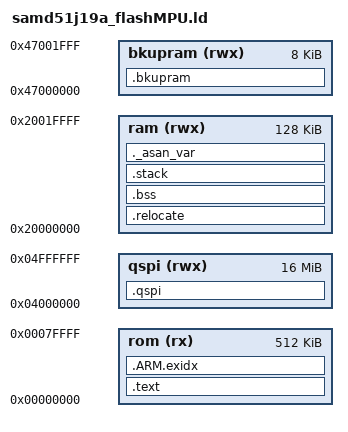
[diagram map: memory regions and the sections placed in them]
/**
 * \file
 *
 * \brief Linker script for running in internal FLASH on the SAMD51J19A
 *
 * Copyright (c) 2019 Microchip Technology Inc.
 *
 * \asf_license_start
 *
 * \page License
 *
 * SPDX-License-Identifier: Apache-2.0
 *
 * Licensed under the Apache License, Version 2.0 (the "License"); you may
 * not use this file except in compliance with the License.
 * You may obtain a copy of the Licence at
 * 
 * http://www.apache.org/licenses/LICENSE-2.0
 * 
 * Unless required by applicable law or agreed to in writing, software
 * distributed under the License is distributed on an AS IS BASIS, WITHOUT
 * WARRANTIES OR CONDITIONS OF ANY KIND, either express or implied.
 * See the License for the specific language governing permissions and
 * limitations under the License.
 *
 * \asf_license_stop
 *
 */


OUTPUT_FORMAT("elf32-littlearm", "elf32-littlearm", "elf32-littlearm")
OUTPUT_ARCH(arm)
SEARCH_DIR(.)

/* Memory Spaces Definitions */
MEMORY
{
  rom      (rx)  : ORIGIN = 0x00000000, LENGTH = 0x00080000
  ram      (rwx) : ORIGIN = 0x20000000, LENGTH = 0x00020000
  bkupram  (rwx) : ORIGIN = 0x47000000, LENGTH = 0x00002000
  qspi     (rwx) : ORIGIN = 0x04000000, LENGTH = 0x01000000
}


/* Initial 32K Flash is used to store kernel functions and
 * initial 512 bytes of RAM is used to store kernel data. */
__privileged_functions_region_size__  = 32K;
__privileged_data_region_size__       = 32K;

__FLASH_segment_start__               = ORIGIN( rom );
__FLASH_segment_end__                 = __FLASH_segment_start__ + LENGTH( rom );

__SRAM_segment_start__                = ORIGIN( ram );
__SRAM_segment_end__                  = __SRAM_segment_start__ + LENGTH( ram );

__privileged_functions_start__        = __FLASH_segment_start__;
__privileged_functions_end__          = __FLASH_segment_start__ + __privileged_functions_region_size__;

__privileged_data_start__             = __SRAM_segment_start__;
__privileged_data_end__               = __SRAM_segment_start__ + __privileged_data_region_size__;



/* The stack size used by the application. NOTE: you need to adjust according to your application. */
/*STACK_SIZE = DEFINED(STACK_SIZE) ? STACK_SIZE : DEFINED(__stack_size__) ? __stack_size__ : 4k;*/


/* Highest address of the user mode stack */
_estack = ORIGIN(ram) + LENGTH(ram); /* end of "RAM_D1" Ram type memory */

_Min_Heap_Size = 4096 ; /* required amount of heap  */
_Min_Stack_Size = 1024 ; /* required amount of stack */



/* Section Definitions */
SECTIONS
{
    


    .text :
    {
        . = ALIGN(4);
        _sfixed = .;
        KEEP(*(.vectors .vectors.*))
         . = ALIGN(4);
        *(privileged_functions)
        . = ALIGN(4);
        FILL(0xDEAD);
        /* Ensure that un-privileged code is placed after the region reserved
         * for privileged kernel code. */
        /* Note that dot (.) actually refers to the byte offset from the start
         * of the current section (.privileged_functions in this case). As a
         * result, setting dot (.) to a value sets the size of the section. */
        . = __privileged_functions_region_size__;
        . = ALIGN(4);
        __syscalls_flash_start__ = .;
        *(freertos_system_calls)
        __syscalls_flash_end__ = .;
        . = ALIGN(4);
        *(.text .text.* .gnu.linkonce.t.*)
        *(.glue_7t) *(.glue_7)
        *(.rodata .rodata* .gnu.linkonce.r.*)
        *(.ARM.extab* .gnu.linkonce.armextab.*)

        /* Support C constructors, and C destructors in both user code
           and the C library. This also provides support for C++ code. */
        . = ALIGN(4);
        KEEP(*(.init))
        . = ALIGN(4);
        __preinit_array_start = .;
        KEEP (*(.preinit_array))
        __preinit_array_end = .;

        . = ALIGN(4);
        __init_array_start = .;
        KEEP (*(SORT(.init_array.*)))
        KEEP (*(.init_array))
        __init_array_end = .;

        . = ALIGN(4);
        KEEP (*crtbegin.o(.ctors))
        KEEP (*(EXCLUDE_FILE (*crtend.o) .ctors))
        KEEP (*(SORT(.ctors.*)))
        KEEP (*crtend.o(.ctors))

        . = ALIGN(4);
        KEEP(*(.fini))

        . = ALIGN(4);
        __fini_array_start = .;
        KEEP (*(.fini_array))
        KEEP (*(SORT(.fini_array.*)))
        __fini_array_end = .;

        KEEP (*crtbegin.o(.dtors))
        KEEP (*(EXCLUDE_FILE (*crtend.o) .dtors))
        KEEP (*(SORT(.dtors.*)))
        KEEP (*crtend.o(.dtors))

        . = ALIGN(4);
        _efixed = .;            /* End of text section */
    } > rom

    /* .ARM.exidx is sorted, so has to go in its own output section.  */
    PROVIDE_HIDDEN (__exidx_start = .);
    .ARM.exidx :
    {
      *(.ARM.exidx* .gnu.linkonce.armexidx.*)
    } > rom
    PROVIDE_HIDDEN (__exidx_end = .);

    . = ALIGN(4);
    _etext = .;

    .relocate : AT (_etext)
    {
        . = ALIGN(4);
        _srelocate = .;
        *(privileged_data)
        . = ALIGN(4);
        FILL(0xDEAD);
        /* Ensure that un-privileged data is placed after the region reserved
         * for privileged kernel data. */
        /* Note that dot (.) actually refers to the byte offset from the start
         * of the current section (.privileged_data in this case). As a result,
         * setting dot (.) to a value sets the size of the section. */
        . = __privileged_data_region_size__;
        *(.ramfunc .ramfunc.*);
        *(.data .data.*);
        . = ALIGN(4);
        _erelocate = .;
    } > ram





    .bkupram (NOLOAD):
    {
        . = ALIGN(8);
        _sbkupram = .;
        *(.bkupram .bkupram.*);
        . = ALIGN(8);
        _ebkupram = .;
    } > bkupram

    .qspi (NOLOAD):
    {
        . = ALIGN(8);
        _sqspi = .;
        *(.qspi .qspi.*);
        . = ALIGN(8);
        _eqspi = .;
    } > qspi

    /* .bss section which is used for uninitialized data */
    .bss (NOLOAD) :
    {
        . = ALIGN(4);
        _sbss = . ;
        _szero = .;
        *(.bss .bss.*)
        *(COMMON)
        . = ALIGN(4);
        _ebss = . ;
        _ezero = .;
    } > ram

    /* stack section */
    .stack BLOCK(8K) : ALIGN(8K)
    {
     
    __user_heap_start__ = .;
    . = ALIGN(8);    
    PROVIDE ( end = . );
    PROVIDE ( _end = . );
    . = . + _Min_Heap_Size;
    . = . + _Min_Stack_Size;
    . = ALIGN(8);
    } > ram

    ._asan_var : 
    {
     . = ALIGN(8);     
    } >ram
  

}
